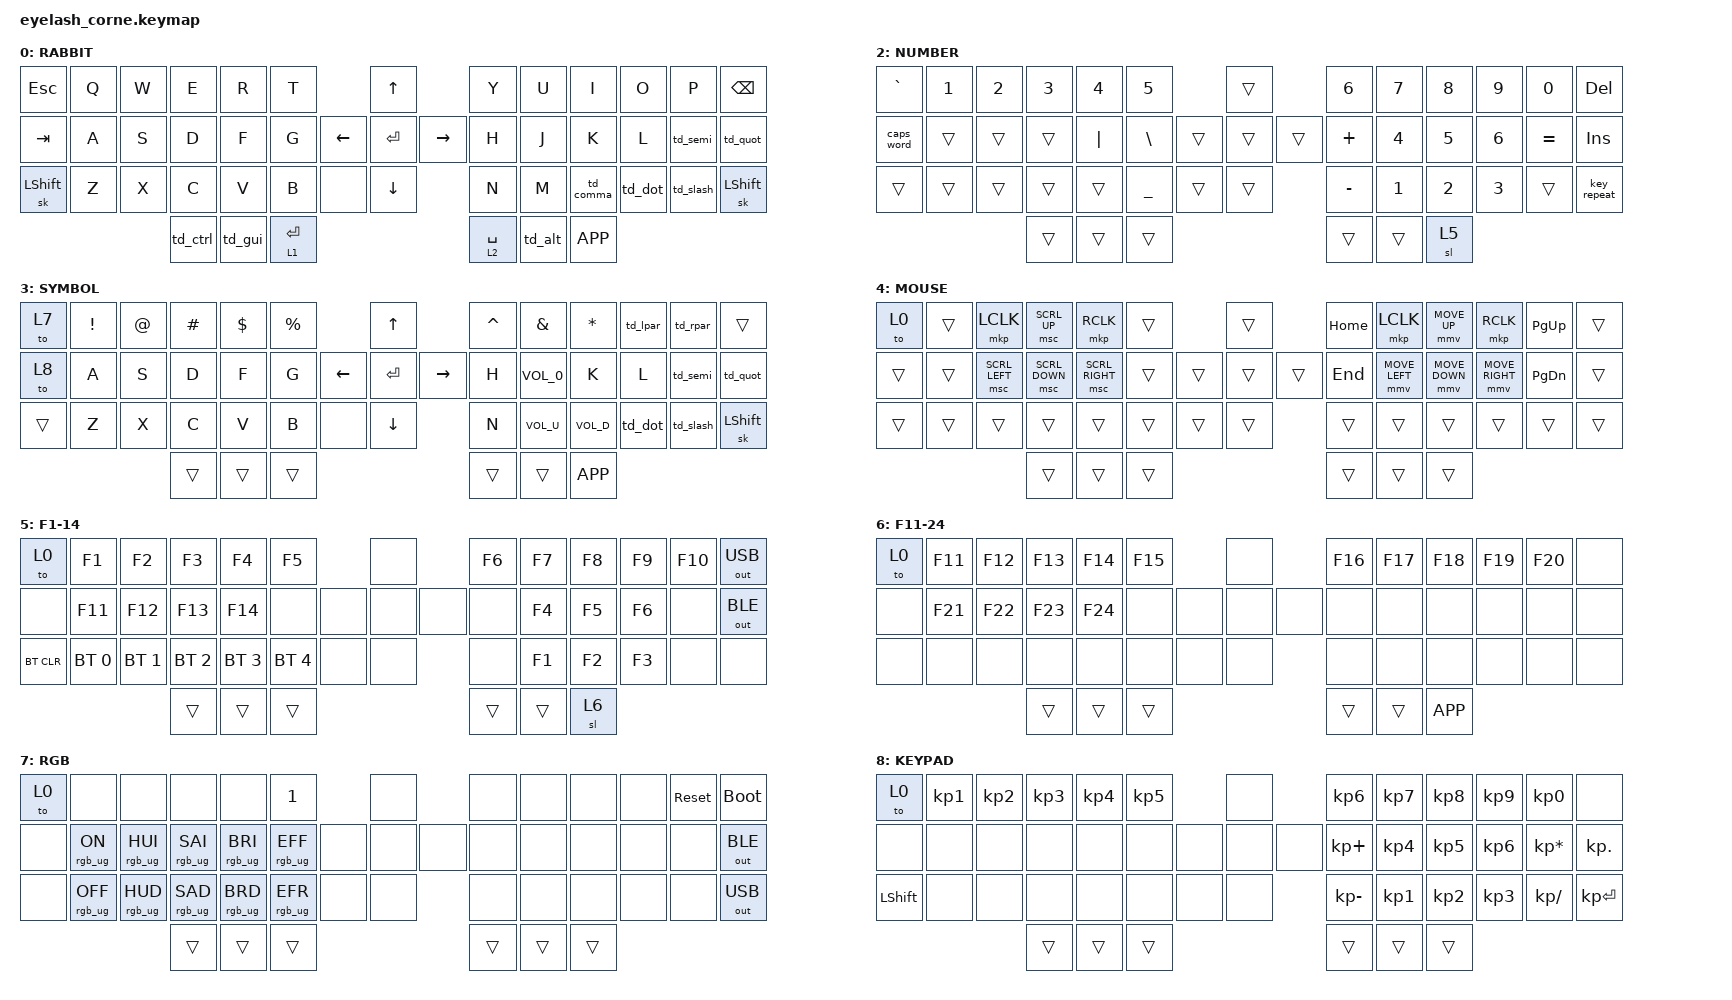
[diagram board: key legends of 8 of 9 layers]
#define ZMK_POINTING_DEFAULT_MOVE_VAL 1200  // 600
#define ZMK_POINTING_DEFAULT_SCRL_VAL 25    // 10

#include <input/processors.dtsi>
#include <zephyr/dt-bindings/input/input-event-codes.h>
#include <behaviors.dtsi>
#include <dt-bindings/zmk/bt.h>
#include <dt-bindings/zmk/keys.h>
#include <dt-bindings/zmk/outputs.h>
#include <dt-bindings/zmk/pointing.h>
#include <dt-bindings/zmk/rgb.h>

#define KP_STAR KP_ASTERISK
#define VOL_U   K_VOL_UP
#define VOL_D   K_VOL_DN
#define VOL_0   K_MUTE

&mmv_input_listener { input-processors = <&zip_xy_scaler 2 1>; };

&msc_input_listener { input-processors = <&zip_scroll_scaler 2 1>; };

&msc {
    acceleration-exponent = <1>;      // 0
    time-to-max-speed-ms = <100>;     // 300
    delay-ms = <0>;                   // 0
};

&mmv {
    time-to-max-speed-ms = <500>;
    acceleration-exponent = <1>;
    trigger-period-ms = <16>;
    // x-input-code = <INPUT_REL_X>;
    // y-input-code = <INPUT_REL_Y>;
    // time-to-max-speed-ms = <300>;
    // acceleration-exponent = <1>;
};

&soft_off { hold-time-ms = <2000>; };

/ {
    behaviors {
        td0: td0 {
            compatible = "zmk,behavior-tap-dance";
            display-name = "Shift/Caps Lock Tap Dance";
            #binding-cells = <0>;
            bindings = <&kp LEFT_SHIFT>, <&kp CAPS>;
        };
        td_slash: td_slash {
            compatible = "zmk,behavior-tap-dance";
            // label = "TD_SLASH";
            #binding-cells = <0>;
            bindings = <&kp FSLH>, <&kp LS(FSLH)>;
        };
        td_dot: td_dot {
            compatible = "zmk,behavior-tap-dance";
            // label = "TD_PERIOD";
            #binding-cells = <0>;
            bindings = <&kp PERIOD>, <&kp LS(PERIOD)>;
        };
        td_comma: td_comma {
            compatible = "zmk,behavior-tap-dance";
            // label = "TD_COMMA";
            #binding-cells = <0>;
            bindings = <&kp COMMA>, <&kp LS(COMMA)>;
        };
        td_semi: td_semi {
            compatible = "zmk,behavior-tap-dance";
            // label = "TD_SEMI";
            #binding-cells = <0>;
            bindings = <&kp SEMI>, <&kp LS(SEMI)>;
        };
        td_quot: td_quot {
            compatible = "zmk,behavior-tap-dance";
            // label = "TD_QUOT";
            #binding-cells = <0>;
            bindings = <&kp SINGLE_QUOTE>, <&kp LS(SINGLE_QUOTE)>;
        };
        td_lpar: td_lpar {
            compatible = "zmk,behavior-tap-dance";
            // label = "TD_LPAR";
            #binding-cells = <0>;
            bindings =
                <&kp LEFT_PARENTHESIS>,
                <&kp LEFT_BRACKET>,
                <&kp LEFT_BRACE>;
        };
        td_rpar: td_rpar {
            compatible = "zmk,behavior-tap-dance";
            // label = "TD_RPAR";
            #binding-cells = <0>;
            bindings =
                <&kp RIGHT_PARENTHESIS>,
                <&kp RIGHT_BRACKET>,
                <&kp RIGHT_BRACE>;
        };
        td_tab_capsword: td_tab_capsword {
            compatible = "zmk,behavior-tap-dance";
            // label = "TD_TAB_CAPSWORD";
            #binding-cells = <0>;
            bindings = <&kp TAB>, <&caps_word>;
        };
        td_esc_r: td_esc_r {
            compatible = "zmk,behavior-tap-dance";
            // label = "TD_ESC_R";
            #binding-cells = <0>;
            bindings = <&kp ESC>, <&sys_reset>;
        };
        td_gui: td_gui {
            compatible = "zmk,behavior-tap-dance";
            // label = "TD_GUI";
            #binding-cells = <0>;
            bindings = <&kp LGUI>, <&sk LGUI>;
        };
        td_alt: td_alt {
            compatible = "zmk,behavior-tap-dance";
            // label = "TD_ALT";
            #binding-cells = <0>;
            bindings = <&kp LALT>, <&sk LALT>;
        };
        td_ctrl: td_ctrl {
            compatible = "zmk,behavior-tap-dance";
            // label = "TD_CTRL";
            #binding-cells = <0>;
            bindings = <&kp LCTRL>, <&sk LCTRL>;
        };
    };

    macros { 

        m_ctl_l: ctrl_left {
            compatible = "zmk,behavior-macro";
            #binding-cells = <0>;
            wait-ms = <40>;
            tap-ms = <40>;
            bindings
                = <&macro_press   &kp LCTRL>
                , <&macro_tap     &kp LEFT>
                , <&macro_release &kp LCTRL>
            ;
        };
        m_ctl_r: ctrl_right {
            compatible = "zmk,behavior-macro";
            #binding-cells = <0>;
            wait-ms = <40>;
            tap-ms = <40>;
            bindings
                = <&macro_press   &kp LCTRL>
                , <&macro_tap     &kp RIGHT>
                , <&macro_release &kp LCTRL>
            ;
        };
    
        m_ctlgui_l: ctrl_gui_left {
            compatible = "zmk,behavior-macro";
            #binding-cells = <0>;
            wait-ms = <40>;
            tap-ms = <40>;
            bindings
                = <&macro_press   &kp LCTRL>
                , <&macro_press   &kp LGUI>
                , <&macro_tap     &kp LEFT>
                , <&macro_release &kp LGUI>
                , <&macro_release &kp LCTRL>
            ;
        };
        m_ctlgui_r: ctrl_gui_right {
            compatible = "zmk,behavior-macro";
            #binding-cells = <0>;
            wait-ms = <40>;
            tap-ms = <40>;
            bindings
                = <&macro_press   &kp LCTRL>
                , <&macro_press   &kp LGUI>
                , <&macro_tap     &kp RIGHT>
                , <&macro_release &kp LGUI>
                , <&macro_release &kp LCTRL>
            ;
        };

        // U+00AB   « LEFT-POINTING DOUBLE ANGLE QUOTATION MARK (&laquo;)   ALT 0171
        // U+00BB   » RIGHT-POINTING DOUBLE ANGLE QUOTATION MARK (&raquo;)  ALT 0187
        // U+2039   ‹ SINGLE LEFT-POINTING ANGLE QUOTATION MARK (&lsaquo;)  ALT 0129
        // U+203A   › SINGLE RIGHT-POINTING ANGLE QUOTATION MARK (&rsaquo;) ALT 0155
        // U+03A9     Omega                                                 ALT 0937

        m_guil_l: guillemets_left {
            compatible = "zmk,behavior-macro";
            #binding-cells = <0>;
            wait-ms = <40>;
            tap-ms = <40>;
            bindings
                = <&macro_press   &kp LALT>
                , <&macro_tap     &kp KP_N0 &kp KP_N1 &kp KP_N7 &kp KP_N1>
                , <&macro_release &kp LALT>
            ;
        };
        m_guil_r: guillemets_right {
            compatible = "zmk,behavior-macro";
            #binding-cells = <0>;
            wait-ms = <40>;
            tap-ms = <40>;
            bindings
                = <&macro_press   &kp LALT>
                , <&macro_tap     &kp KP_N0 &kp KP_N1 &kp KP_N8 &kp KP_N7>
                , <&macro_release &kp LALT>
            ;
        };
        m_aq_l: angle_quote_left {
            compatible = "zmk,behavior-macro";
            #binding-cells = <0>;
            wait-ms = <40>;
            tap-ms = <40>;
            bindings
                = <&macro_press   &kp LALT>
                , <&macro_tap     &kp KP_N0 &kp KP_N1 &kp KP_N2 &kp KP_N9>
                , <&macro_release &kp LALT>
            ;
        };
        m_aq_r: angle_quote_right {
            compatible = "zmk,behavior-macro";
            #binding-cells = <0>;
            wait-ms = <40>;
            tap-ms = <40>;
            bindings
                = <&macro_press   &kp LALT>
                , <&macro_tap     &kp KP_N0 &kp KP_N1 &kp KP_N5 &kp KP_N5>
                , <&macro_release &kp LALT>
            ;
        };
        m_omega: omega {
            compatible = "zmk,behavior-macro";
            #binding-cells = <0>;
            wait-ms = <40>;
            tap-ms = <40>;
            bindings
                = <&macro_press   &kp LALT>
                , <&macro_tap     &kp KP_N0 &kp KP_N9 &kp KP_N3 &kp KP_N7>
                , <&macro_release &kp LALT>
            ;
        };
    };

    rgb_encoder: rgb_encoder {
        compatible = "zmk,behavior-sensor-rotate";
        #sensor-binding-cells = <0>;
        bindings = <&rgb_ug RGB_BRI>, <&rgb_ug RGB_BRD>;
    };

    scroll_encoder: scroll_encoder {
        compatible = "zmk,behavior-sensor-rotate";
        #sensor-binding-cells = <0>;
        bindings = <&msc SCRL_DOWN>, <&msc SCRL_UP>;

        tap-ms = <100>;
    };

    combos {
        compatible = "zmk,combos";

        softoff {
            bindings = <&soft_off>;
            key-positions = <1 15 29>;
        };
    };

    conditional_layers {
        compatible = "zmk,conditional-layers";
        tri_layer {
            if-layers = <1 2>;
            then-layer = <3>;
        };
    };

    keymap {
        compatible = "zmk,keymap";

        base_layer { // 0
            display-name = "RABBIT";
            bindings = <
//         |         |         |         |         |       .         .          .          |         |         |         |         |         |         .
&kp ESC    &kp Q     &kp W     &kp E     &kp R     &kp T             &kp UP                &kp Y     &kp U     &kp I     &kp O     &kp P     &kp BSPC
&kp TAB    &kp A     &kp S     &kp D     &kp F     &kp G   &kp LEFT  &kp ENTER  &kp RIGHT  &kp H     &kp J     &kp K     &kp L     &td_semi  &td_quot
&sk LSHFT  &kp Z     &kp X     &kp C     &kp V     &kp B   &none     &kp DOWN              &kp N     &kp M     &td_comma &td_dot   &td_slash &sk LSHFT
                               &td_ctrl  &td_gui   &lt 1 ENTER                          &lt 2 SPACE  &td_alt   &kp K_APP
//                             &kp LCTRL &kp LGUI  &lt 1 ENTER                          &lt 2 SPACE  &kp LALT  &kp K_APP
            >;
            sensor-bindings = <&inc_dec_kp C_VOLUME_UP C_VOLUME_DOWN>;
        };

        motion_layer { // 1 LOWER
            display-name = "MOTION";
            bindings = <
//         |         |         |         |         |       .         .          .          |         |         |         |         |         |         .
&kp TILDE  &trans    &mkp LCLK &msc SCRL_UP 
                                         &mkp RCLK &trans            &m_ctl_l              &kp HOME  &trans    &kp UP    &trans    &kp PG_UP &trans
&to 4      &trans    &msc SCRL_LEFT 
                               &msc SCRL_DOWN 
                                         &msc SCRL_RIGHT
                                                   &trans  &m_ctlgui_l &trans  &m_ctlgui_r &kp END   &kp LEFT  &kp DOWN  &kp RIGHT &kp PG_DN &trans 
&trans     &m_guil_l &m_guil_r  &m_omega  &m_aq_l  &m_aq_r &trans      &m_ctl_r   &trans   &trans    &trans    &trans    &trans    &trans    &trans 
                                &trans    &trans   &trans                                  &trans    &trans    &trans
            >;
            sensor-bindings = <&scroll_encoder>;
        };

        number_layer { // 2 RAISE
            display-name = "NUMBER";
            bindings = <
//         |         |         |         |         |       .         .          .          |         |         |         |         |         |         .
&kp GRAVE  &kp N1    &kp N2    &kp N3    &kp N4    &kp N5            &trans                &kp N6    &kp N7    &kp N8    &kp N9    &kp N0    &kp DEL
&caps_word &trans    &trans    &trans    &kp PIPE  &kp BSLH  &trans  &trans     &trans     &kp PLUS  &kp N4    &kp N5    &kp N6    &kp EQUAL &kp INS
&trans     &trans    &trans    &trans    &trans    &kp UNDER &trans  &trans                &kp MINUS &kp N1    &kp N2    &kp N3    &trans    &key_repeat 
                               &trans    &trans    &trans                                  &trans    &trans    &sl 5
            >;
            sensor-bindings = <&scroll_encoder>;
        };

        symbol_layer { // 3 (RAISE + LOWER)
            display-name = "SYMBOL";
            bindings = <
//         |         |         |         |         |       .         .          .          |         |         |         |         |         |         .
&to 7      &kp EXCL  &kp AT    &kp HASH  &kp DLLR  &kp PRCNT         &kp UP                &kp CARET &kp AMPS  &kp STAR  &td_lpar  &td_rpar  &trans
&to 8      &kp A     &kp S     &kp D     &kp F     &kp G   &kp LEFT  &kp ENTER  &kp RIGHT  &kp H     &kp VOL_0 &kp K     &kp L     &td_semi  &td_quot
&trans     &kp Z     &kp X     &kp C     &kp V     &kp B   &none     &kp DOWN              &kp N     &kp VOL_U &kp VOL_D &td_dot   &td_slash &sk LSHFT
                               &trans    &trans    &trans                                  &trans    &trans    &kp K_APP
            >;
            sensor-bindings = <&scroll_encoder>;
        };

        mouse_layer { // 4 MOUSE EMULATION
            display-name = "MOUSE";
            bindings = <
//         |         |         |         |         |       .         .          .          |         |         |         |         |         |         .
&to 0      &trans    &mkp LCLK &msc SCRL_UP 
                                         &mkp RCLK &trans            &trans                &kp HOME  &mkp LCLK &mmv MOVE_UP   
                                                                                                                         &mkp RCLK &kp PG_UP &trans
&trans     &trans    &msc SCRL_LEFT                                                        //
                               &msc SCRL_DOWN                                              //
                                         &msc SCRL_RIGHT                                   //
                                                   &trans  &trans    &trans     &trans     &kp END   &mmv MOVE_LEFT  
                                                                                                                &mmv MOVE_DOWN  
                                                                                                                         &mmv MOVE_RIGHT 
                                                                                                                                   &kp PG_DN &trans 
&trans     &trans    &trans    &trans    &trans    &trans  &trans    &trans                &trans    &trans    &trans    &trans    &trans    &trans 
                               &trans    &trans    &trans                                  &trans    &trans    &trans
            >;
            sensor-bindings = <&scroll_encoder>;
        };

        func_layer { // 5 Function keys F1-14
            display-name = "F1-14";
            bindings = <
//         |       |         |         |         |       .         .          .          |         |         |         |         |         |         .
&to 0      &kp F1  &kp F2    &kp F3    &kp F4    &kp F5            &none                 &kp F6    &kp F7    &kp F8    &kp F9    &kp F10   &out OUT_USB
&none      &kp F11 &kp F12   &kp F13   &kp F14   &none    &none    &none      &none      &none     &kp F4    &kp F5    &kp F6    &none     &out OUT_BLE
&bt  BT_CLR                                                                                //
            &bt BT_SEL 0                                                                   //
                     &bt BT_SEL 1                                                          //
                               &bt BT_SEL 2                                                //
                                          &bt BT_SEL 3                                     //
                                                   &bt BT_SEL 4                            // 
                                                            &none    &none                 &none     &kp F1    &kp F2    &kp F3    &none     &none
                                &trans    &trans   &trans                                  &trans    &trans    &sl 6
            >;
            sensor-bindings = <&scroll_encoder>;
        };
        func2_layer { // 6 Function Keys F11-F24
            display-name = "F11-24";
            bindings = <
//         |         |         |         |         |       .         .          .          |         |         |         |         |         |         .
&to 0      &kp F11   &kp F12   &kp F13   &kp F14   &kp F15           &none                 &kp F16   &kp F17   &kp F18   &kp F19   &kp F20   &none
&none      &kp F21   &kp F22   &kp F23   &kp F24   &none   &none     &none     &none       &none     &none     &none     &none     &none     &none
&none      &none     &none     &none     &none     &none   &none     &none                 &none     &none     &none     &none     &none     &none                    
                               &trans    &trans    &trans                                  &trans    &trans    &kp K_APP
            >;
            sensor-bindings = <&scroll_encoder>;
        };

        rgb_layer  { // 7
            display-name = "RGB";
            bindings = <
//         |               |               |               |               |                .       .          .       |         |         |         |         |         |         .
&to 0      &none           &none           &none           &none           &kp N1                    &none             &none     &none     &none     &none     &sys_reset &bootloader
&none      &rgb_ug RGB_ON  &rgb_ug RGB_HUI &rgb_ug RGB_SAI &rgb_ug RGB_BRI &rgb_ug RGB_EFF  &none    &none     &none   &none     &none     &none     &none     &none      &out OUT_BLE
&none      &rgb_ug RGB_OFF &rgb_ug RGB_HUD &rgb_ug RGB_SAD &rgb_ug RGB_BRD &rgb_ug RGB_EFR  &none    &none             &none     &none     &none     &none     &none      &out OUT_USB
                                                           &trans          &trans           &trans                     &trans    &trans    &trans
            >;
            sensor-bindings = <&scroll_encoder>;
        };

        keypad_layer { // 8
            display-name = "KEYPAD";
            bindings = <
//         |             |             |             |             |               .        .        .       |             |          |          |          |             |         
&to 0      &kp KP_N1     &kp KP_N2     &kp KP_N3     &kp KP_N4     &kp KP_N5                &none            &kp KP_N6     &kp KP_N7  &kp KP_N8  &kp KP_N9  &kp KP_N0     &none
&none      &none         &none         &none         &none         &none           &none    &none    &none   &kp KP_PLUS   &kp KP_N4  &kp KP_N5  &kp KP_N6  &kp KP_STAR   &kp KP_DOT
&kp LSHFT  &none         &none         &none         &none         &none           &none    &none            &kp KP_MINUS  &kp KP_N1  &kp KP_N2  &kp KP_N3  &kp KP_SLASH  &kp KP_ENTER 
                         &trans        &trans        &trans                                                  &trans        &trans     &trans
            >;
            sensor-bindings = <&scroll_encoder>;
        };
    };
};

// 
// &kp C_MUTE  &kp SCROLLLOCK  &kp PAUSE_BREAK &key_repeat
// RGB_TOG (0,0-100,0-100)

